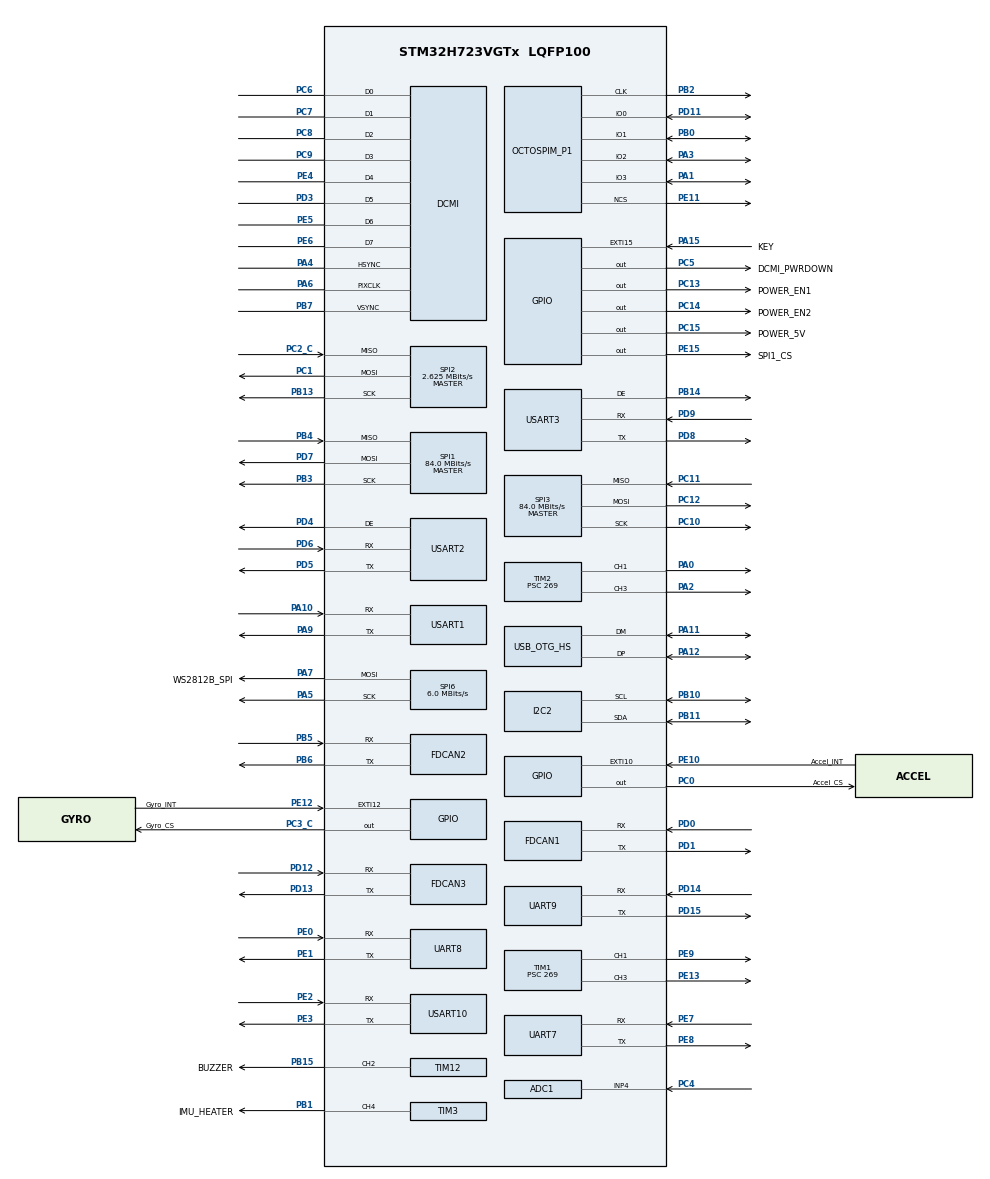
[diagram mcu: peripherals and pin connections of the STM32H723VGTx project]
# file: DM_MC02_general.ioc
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ADC1.Channel-1\#ChannelRegularConversion=ADC_CHANNEL_4
ADC1.ClockPrescaler=ADC_CLOCK_ASYNC_DIV1
ADC1.NbrOfConversionFlag=1
ADC1.OffsetNumber-1\#ChannelRegularConversion=ADC_OFFSET_NONE
ADC1.OffsetSignedSaturation-1\#ChannelRegularConversion=DISABLE
ADC1.Rank-1\#ChannelRegularConversion=1
ADC1.Resolution=ADC_RESOLUTION_16B
ADC1.SamplingTime-1\#ChannelRegularConversion=ADC_SAMPLETIME_64CYCLES_5
ADC1.master=1
ADC3.Channel-0\#ChannelRegularConversion=ADC_CHANNEL_TEMPSENSOR
ADC3.ClockPrescalerADC3=ADC_CLOCK_ASYNC_DIV4
ADC3.NbrOfConversionFlag=1
ADC3.OffsetNumber-0\#ChannelRegularConversion=ADC_OFFSET_NONE
ADC3.OffsetSign-0\#ChannelRegularConversion=ADC3_OFFSET_SIGN_NEGATIVE
ADC3.Rank-0\#ChannelRegularConversion=1
ADC3.ResolutionADC3=ADC_RESOLUTION_12B
ADC3.SamplingTime-0\#ChannelRegularConversion=ADC3_SAMPLETIME_640CYCLES_5
CORTEX_M7.AccessPermission-Cortex_Memory_Protection_Unit_Region0_Settings=MPU_REGION_FULL_ACCESS
CORTEX_M7.BaseAddress-Cortex_Memory_Protection_Unit_Region0_Settings=0x24000000
CORTEX_M7.CPU_DCache=Disabled
CORTEX_M7.CPU_ICache=Disabled
CORTEX_M7.Enable-Cortex_Memory_Protection_Unit_Region0_Settings=MPU_REGION_ENABLE
CORTEX_M7.IsBufferable-Cortex_Memory_Protection_Unit_Region0_Settings=MPU_ACCESS_BUFFERABLE
CORTEX_M7.IsCacheable-Cortex_Memory_Protection_Unit_Region0_Settings=MPU_ACCESS_CACHEABLE
CORTEX_M7.MPU_Control=__NULL
CORTEX_M7.Size-Cortex_Memory_Protection_Unit_Region0_Settings=MPU_REGION_SIZE_512KB
CORTEX_M7.TypeExtField-Cortex_Memory_Protection_Unit_Region0_Settings=MPU_TEX_LEVEL1
CORTEX_M7.default_mode_Activation=0
DCMI.JPEGMode=DCMI_JPEG_ENABLE
DCMI.PCKPolarity=DCMI_PCKPOLARITY_RISING
Dma.DCMI.10.Direction=DMA_PERIPH_TO_MEMORY
Dma.DCMI.10.EventEnable=DISABLE
Dma.DCMI.10.FIFOMode=DMA_FIFOMODE_DISABLE
Dma.DCMI.10.Instance=DMA2_Stream5
Dma.DCMI.10.MemDataAlignment=DMA_MDATAALIGN_WORD
Dma.DCMI.10.MemInc=DMA_MINC_ENABLE
Dma.DCMI.10.Mode=DMA_NORMAL
Dma.DCMI.10.PeriphDataAlignment=DMA_PDATAALIGN_WORD
Dma.DCMI.10.PeriphInc=DMA_PINC_DISABLE
Dma.DCMI.10.Polarity=HAL_DMAMUX_REQ_GEN_RISING
Dma.DCMI.10.Priority=DMA_PRIORITY_LOW
Dma.DCMI.10.RequestNumber=1
Dma.DCMI.10.SignalID=NONE
Dma.DCMI.10.SyncEnable=DISABLE
Dma.DCMI.10.SyncPolarity=HAL_DMAMUX_SYNC_NO_EVENT
Dma.DCMI.10.SyncRequestNumber=1
Dma.DCMI.10.SyncSignalID=NONE
Dma.Request0=USART1_RX
Dma.Request1=USART1_TX
Dma.Request10=DCMI
Dma.Request11=SPI1_TX
Dma.Request12=SPI1_RX
Dma.Request13=UART7_TX
Dma.Request14=USART10_RX
Dma.Request2=USART2_RX
Dma.Request3=USART2_TX
Dma.Request4=USART3_RX
Dma.Request5=UART8_RX
Dma.Request6=UART9_RX
Dma.Request7=UART7_RX
Dma.Request8=SPI2_RX
Dma.Request9=SPI2_TX
Dma.SPI1_RX.12.Direction=DMA_PERIPH_TO_MEMORY
Dma.SPI1_RX.12.EventEnable=DISABLE
Dma.SPI1_RX.12.FIFOMode=DMA_FIFOMODE_DISABLE
Dma.SPI1_RX.12.Instance=DMA2_Stream6
Dma.SPI1_RX.12.MemDataAlignment=DMA_MDATAALIGN_BYTE
Dma.SPI1_RX.12.MemInc=DMA_MINC_ENABLE
Dma.SPI1_RX.12.Mode=DMA_NORMAL
Dma.SPI1_RX.12.PeriphDataAlignment=DMA_PDATAALIGN_BYTE
Dma.SPI1_RX.12.PeriphInc=DMA_PINC_DISABLE
Dma.SPI1_RX.12.Polarity=HAL_DMAMUX_REQ_GEN_RISING
Dma.SPI1_RX.12.Priority=DMA_PRIORITY_MEDIUM
Dma.SPI1_RX.12.RequestNumber=1
Dma.SPI1_RX.12.SignalID=NONE
Dma.SPI1_RX.12.SyncEnable=DISABLE
Dma.SPI1_RX.12.SyncPolarity=HAL_DMAMUX_SYNC_NO_EVENT
Dma.SPI1_RX.12.SyncRequestNumber=1
Dma.SPI1_RX.12.SyncSignalID=NONE
Dma.SPI1_TX.11.Direction=DMA_MEMORY_TO_PERIPH
Dma.SPI1_TX.11.EventEnable=DISABLE
Dma.SPI1_TX.11.FIFOMode=DMA_FIFOMODE_DISABLE
Dma.SPI1_TX.11.Instance=DMA2_Stream7
Dma.SPI1_TX.11.MemDataAlignment=DMA_MDATAALIGN_BYTE
Dma.SPI1_TX.11.MemInc=DMA_MINC_ENABLE
Dma.SPI1_TX.11.Mode=DMA_NORMAL
Dma.SPI1_TX.11.PeriphDataAlignment=DMA_PDATAALIGN_BYTE
Dma.SPI1_TX.11.PeriphInc=DMA_PINC_DISABLE
Dma.SPI1_TX.11.Polarity=HAL_DMAMUX_REQ_GEN_RISING
Dma.SPI1_TX.11.Priority=DMA_PRIORITY_MEDIUM
Dma.SPI1_TX.11.RequestNumber=1
Dma.SPI1_TX.11.SignalID=NONE
Dma.SPI1_TX.11.SyncEnable=DISABLE
Dma.SPI1_TX.11.SyncPolarity=HAL_DMAMUX_SYNC_NO_EVENT
Dma.SPI1_TX.11.SyncRequestNumber=1
Dma.SPI1_TX.11.SyncSignalID=NONE
Dma.SPI2_RX.8.Direction=DMA_PERIPH_TO_MEMORY
Dma.SPI2_RX.8.EventEnable=DISABLE
Dma.SPI2_RX.8.FIFOMode=DMA_FIFOMODE_DISABLE
Dma.SPI2_RX.8.Instance=DMA2_Stream2
Dma.SPI2_RX.8.MemDataAlignment=DMA_MDATAALIGN_BYTE
Dma.SPI2_RX.8.MemInc=DMA_MINC_ENABLE
Dma.SPI2_RX.8.Mode=DMA_NORMAL
Dma.SPI2_RX.8.PeriphDataAlignment=DMA_PDATAALIGN_BYTE
Dma.SPI2_RX.8.PeriphInc=DMA_PINC_DISABLE
Dma.SPI2_RX.8.Polarity=HAL_DMAMUX_REQ_GEN_RISING
Dma.SPI2_RX.8.Priority=DMA_PRIORITY_VERY_HIGH
Dma.SPI2_RX.8.RequestNumber=1
Dma.SPI2_RX.8.SignalID=NONE
Dma.SPI2_RX.8.SyncEnable=DISABLE
Dma.SPI2_RX.8.SyncPolarity=HAL_DMAMUX_SYNC_NO_EVENT
Dma.SPI2_RX.8.SyncRequestNumber=1
Dma.SPI2_RX.8.SyncSignalID=NONE
Dma.SPI2_TX.9.Direction=DMA_MEMORY_TO_PERIPH
Dma.SPI2_TX.9.EventEnable=DISABLE
Dma.SPI2_TX.9.FIFOMode=DMA_FIFOMODE_DISABLE
Dma.SPI2_TX.9.Instance=DMA2_Stream3
Dma.SPI2_TX.9.MemDataAlignment=DMA_MDATAALIGN_BYTE
Dma.SPI2_TX.9.MemInc=DMA_MINC_ENABLE
Dma.SPI2_TX.9.Mode=DMA_NORMAL
Dma.SPI2_TX.9.PeriphDataAlignment=DMA_PDATAALIGN_BYTE
Dma.SPI2_TX.9.PeriphInc=DMA_PINC_DISABLE
Dma.SPI2_TX.9.Polarity=HAL_DMAMUX_REQ_GEN_RISING
Dma.SPI2_TX.9.Priority=DMA_PRIORITY_HIGH
Dma.SPI2_TX.9.RequestNumber=1
Dma.SPI2_TX.9.SignalID=NONE
Dma.SPI2_TX.9.SyncEnable=DISABLE
Dma.SPI2_TX.9.SyncPolarity=HAL_DMAMUX_SYNC_NO_EVENT
Dma.SPI2_TX.9.SyncRequestNumber=1
Dma.SPI2_TX.9.SyncSignalID=NONE
Dma.UART7_RX.7.Direction=DMA_PERIPH_TO_MEMORY
Dma.UART7_RX.7.EventEnable=DISABLE
Dma.UART7_RX.7.FIFOMode=DMA_FIFOMODE_DISABLE
Dma.UART7_RX.7.Instance=DMA2_Stream1
Dma.UART7_RX.7.MemDataAlignment=DMA_MDATAALIGN_BYTE
Dma.UART7_RX.7.MemInc=DMA_MINC_ENABLE
Dma.UART7_RX.7.Mode=DMA_NORMAL
Dma.UART7_RX.7.PeriphDataAlignment=DMA_PDATAALIGN_BYTE
Dma.UART7_RX.7.PeriphInc=DMA_PINC_DISABLE
Dma.UART7_RX.7.Polarity=HAL_DMAMUX_REQ_GEN_RISING
Dma.UART7_RX.7.Priority=DMA_PRIORITY_VERY_HIGH
Dma.UART7_RX.7.RequestNumber=1
Dma.UART7_RX.7.SignalID=NONE
Dma.UART7_RX.7.SyncEnable=DISABLE
Dma.UART7_RX.7.SyncPolarity=HAL_DMAMUX_SYNC_NO_EVENT
Dma.UART7_RX.7.SyncRequestNumber=1
Dma.UART7_RX.7.SyncSignalID=NONE
Dma.UART7_TX.13.Direction=DMA_MEMORY_TO_PERIPH
Dma.UART7_TX.13.EventEnable=DISABLE
Dma.UART7_TX.13.FIFOMode=DMA_FIFOMODE_DISABLE
Dma.UART7_TX.13.Instance=DMA2_Stream4
Dma.UART7_TX.13.MemDataAlignment=DMA_MDATAALIGN_BYTE
Dma.UART7_TX.13.MemInc=DMA_MINC_ENABLE
Dma.UART7_TX.13.Mode=DMA_NORMAL
Dma.UART7_TX.13.PeriphDataAlignment=DMA_PDATAALIGN_BYTE
Dma.UART7_TX.13.PeriphInc=DMA_PINC_DISABLE
Dma.UART7_TX.13.Polarity=HAL_DMAMUX_REQ_GEN_RISING
Dma.UART7_TX.13.Priority=DMA_PRIORITY_VERY_HIGH
Dma.UART7_TX.13.RequestNumber=1
Dma.UART7_TX.13.SignalID=NONE
Dma.UART7_TX.13.SyncEnable=DISABLE
Dma.UART7_TX.13.SyncPolarity=HAL_DMAMUX_SYNC_NO_EVENT
Dma.UART7_TX.13.SyncRequestNumber=1
Dma.UART7_TX.13.SyncSignalID=NONE
Dma.UART8_RX.5.Direction=DMA_PERIPH_TO_MEMORY
Dma.UART8_RX.5.EventEnable=DISABLE
Dma.UART8_RX.5.FIFOMode=DMA_FIFOMODE_DISABLE
Dma.UART8_RX.5.Instance=DMA1_Stream6
Dma.UART8_RX.5.MemDataAlignment=DMA_MDATAALIGN_BYTE
Dma.UART8_RX.5.MemInc=DMA_MINC_ENABLE
Dma.UART8_RX.5.Mode=DMA_NORMAL
Dma.UART8_RX.5.PeriphDataAlignment=DMA_PDATAALIGN_BYTE
Dma.UART8_RX.5.PeriphInc=DMA_PINC_DISABLE
Dma.UART8_RX.5.Polarity=HAL_DMAMUX_REQ_GEN_RISING
Dma.UART8_RX.5.Priority=DMA_PRIORITY_MEDIUM
Dma.UART8_RX.5.RequestNumber=1
Dma.UART8_RX.5.SignalID=NONE
Dma.UART8_RX.5.SyncEnable=DISABLE
Dma.UART8_RX.5.SyncPolarity=HAL_DMAMUX_SYNC_NO_EVENT
Dma.UART8_RX.5.SyncRequestNumber=1
Dma.UART8_RX.5.SyncSignalID=NONE
Dma.UART9_RX.6.Direction=DMA_PERIPH_TO_MEMORY
Dma.UART9_RX.6.EventEnable=DISABLE
Dma.UART9_RX.6.FIFOMode=DMA_FIFOMODE_DISABLE
Dma.UART9_RX.6.Instance=DMA1_Stream7
Dma.UART9_RX.6.MemDataAlignment=DMA_MDATAALIGN_BYTE
Dma.UART9_RX.6.MemInc=DMA_MINC_ENABLE
Dma.UART9_RX.6.Mode=DMA_NORMAL
Dma.UART9_RX.6.PeriphDataAlignment=DMA_PDATAALIGN_BYTE
Dma.UART9_RX.6.PeriphInc=DMA_PINC_DISABLE
Dma.UART9_RX.6.Polarity=HAL_DMAMUX_REQ_GEN_RISING
Dma.UART9_RX.6.Priority=DMA_PRIORITY_MEDIUM
Dma.UART9_RX.6.RequestNumber=1
Dma.UART9_RX.6.SignalID=NONE
Dma.UART9_RX.6.SyncEnable=DISABLE
Dma.UART9_RX.6.SyncPolarity=HAL_DMAMUX_SYNC_NO_EVENT
Dma.UART9_RX.6.SyncRequestNumber=1
Dma.UART9_RX.6.SyncSignalID=NONE
Dma.USART10_RX.14.Direction=DMA_PERIPH_TO_MEMORY
Dma.USART10_RX.14.EventEnable=DISABLE
Dma.USART10_RX.14.FIFOMode=DMA_FIFOMODE_DISABLE
Dma.USART10_RX.14.Instance=DMA1_Stream5
Dma.USART10_RX.14.MemDataAlignment=DMA_MDATAALIGN_BYTE
Dma.USART10_RX.14.MemInc=DMA_MINC_ENABLE
Dma.USART10_RX.14.Mode=DMA_NORMAL
Dma.USART10_RX.14.PeriphDataAlignment=DMA_PDATAALIGN_BYTE
Dma.USART10_RX.14.PeriphInc=DMA_PINC_DISABLE
Dma.USART10_RX.14.Polarity=HAL_DMAMUX_REQ_GEN_RISING
Dma.USART10_RX.14.Priority=DMA_PRIORITY_HIGH
Dma.USART10_RX.14.RequestNumber=1
Dma.USART10_RX.14.SignalID=NONE
Dma.USART10_RX.14.SyncEnable=DISABLE
Dma.USART10_RX.14.SyncPolarity=HAL_DMAMUX_SYNC_NO_EVENT
Dma.USART10_RX.14.SyncRequestNumber=1
Dma.USART10_RX.14.SyncSignalID=NONE
Dma.USART1_RX.0.Direction=DMA_PERIPH_TO_MEMORY
Dma.USART1_RX.0.EventEnable=DISABLE
Dma.USART1_RX.0.FIFOMode=DMA_FIFOMODE_DISABLE
Dma.USART1_RX.0.Instance=DMA1_Stream0
Dma.USART1_RX.0.MemDataAlignment=DMA_MDATAALIGN_BYTE
Dma.USART1_RX.0.MemInc=DMA_MINC_ENABLE
Dma.USART1_RX.0.Mode=DMA_NORMAL
Dma.USART1_RX.0.PeriphDataAlignment=DMA_PDATAALIGN_BYTE
Dma.USART1_RX.0.PeriphInc=DMA_PINC_DISABLE
Dma.USART1_RX.0.Polarity=HAL_DMAMUX_REQ_GEN_RISING
Dma.USART1_RX.0.Priority=DMA_PRIORITY_VERY_HIGH
Dma.USART1_RX.0.RequestNumber=1
Dma.USART1_RX.0.SignalID=NONE
Dma.USART1_RX.0.SyncEnable=DISABLE
Dma.USART1_RX.0.SyncPolarity=HAL_DMAMUX_SYNC_NO_EVENT
Dma.USART1_RX.0.SyncRequestNumber=1
Dma.USART1_RX.0.SyncSignalID=NONE
Dma.USART1_TX.1.Direction=DMA_MEMORY_TO_PERIPH
Dma.USART1_TX.1.EventEnable=DISABLE
Dma.USART1_TX.1.FIFOMode=DMA_FIFOMODE_DISABLE
Dma.USART1_TX.1.Instance=DMA1_Stream1
Dma.USART1_TX.1.MemDataAlignment=DMA_MDATAALIGN_BYTE
Dma.USART1_TX.1.MemInc=DMA_MINC_ENABLE
Dma.USART1_TX.1.Mode=DMA_NORMAL
Dma.USART1_TX.1.PeriphDataAlignment=DMA_PDATAALIGN_BYTE
Dma.USART1_TX.1.PeriphInc=DMA_PINC_DISABLE
Dma.USART1_TX.1.Polarity=HAL_DMAMUX_REQ_GEN_RISING
Dma.USART1_TX.1.Priority=DMA_PRIORITY_VERY_HIGH
Dma.USART1_TX.1.RequestNumber=1
Dma.USART1_TX.1.SignalID=NONE
Dma.USART1_TX.1.SyncEnable=DISABLE
Dma.USART1_TX.1.SyncPolarity=HAL_DMAMUX_SYNC_NO_EVENT
Dma.USART1_TX.1.SyncRequestNumber=1
Dma.USART1_TX.1.SyncSignalID=NONE
Dma.USART2_RX.2.Direction=DMA_PERIPH_TO_MEMORY
Dma.USART2_RX.2.EventEnable=DISABLE
Dma.USART2_RX.2.FIFOMode=DMA_FIFOMODE_DISABLE
Dma.USART2_RX.2.Instance=DMA1_Stream2
Dma.USART2_RX.2.MemDataAlignment=DMA_MDATAALIGN_BYTE
Dma.USART2_RX.2.MemInc=DMA_MINC_ENABLE
Dma.USART2_RX.2.Mode=DMA_NORMAL
Dma.USART2_RX.2.PeriphDataAlignment=DMA_PDATAALIGN_BYTE
Dma.USART2_RX.2.PeriphInc=DMA_PINC_DISABLE
Dma.USART2_RX.2.Polarity=HAL_DMAMUX_REQ_GEN_RISING
Dma.USART2_RX.2.Priority=DMA_PRIORITY_VERY_HIGH
Dma.USART2_RX.2.RequestNumber=1
Dma.USART2_RX.2.SignalID=NONE
Dma.USART2_RX.2.SyncEnable=DISABLE
Dma.USART2_RX.2.SyncPolarity=HAL_DMAMUX_SYNC_NO_EVENT
Dma.USART2_RX.2.SyncRequestNumber=1
Dma.USART2_RX.2.SyncSignalID=NONE
Dma.USART2_TX.3.Direction=DMA_MEMORY_TO_PERIPH
Dma.USART2_TX.3.EventEnable=DISABLE
Dma.USART2_TX.3.FIFOMode=DMA_FIFOMODE_DISABLE
Dma.USART2_TX.3.Instance=DMA1_Stream3
Dma.USART2_TX.3.MemDataAlignment=DMA_MDATAALIGN_BYTE
Dma.USART2_TX.3.MemInc=DMA_MINC_ENABLE
Dma.USART2_TX.3.Mode=DMA_NORMAL
Dma.USART2_TX.3.PeriphDataAlignment=DMA_PDATAALIGN_BYTE
Dma.USART2_TX.3.PeriphInc=DMA_PINC_DISABLE
Dma.USART2_TX.3.Polarity=HAL_DMAMUX_REQ_GEN_RISING
Dma.USART2_TX.3.Priority=DMA_PRIORITY_VERY_HIGH
Dma.USART2_TX.3.RequestNumber=1
Dma.USART2_TX.3.SignalID=NONE
Dma.USART2_TX.3.SyncEnable=DISABLE
Dma.USART2_TX.3.SyncPolarity=HAL_DMAMUX_SYNC_NO_EVENT
Dma.USART2_TX.3.SyncRequestNumber=1
Dma.USART2_TX.3.SyncSignalID=NONE
Dma.USART3_RX.4.Direction=DMA_PERIPH_TO_MEMORY
Dma.USART3_RX.4.EventEnable=DISABLE
Dma.USART3_RX.4.FIFOMode=DMA_FIFOMODE_DISABLE
Dma.USART3_RX.4.Instance=DMA1_Stream4
Dma.USART3_RX.4.MemDataAlignment=DMA_MDATAALIGN_BYTE
Dma.USART3_RX.4.MemInc=DMA_MINC_ENABLE
Dma.USART3_RX.4.Mode=DMA_NORMAL
Dma.USART3_RX.4.PeriphDataAlignment=DMA_PDATAALIGN_BYTE
Dma.USART3_RX.4.PeriphInc=DMA_PINC_DISABLE
Dma.USART3_RX.4.Polarity=HAL_DMAMUX_REQ_GEN_RISING
Dma.USART3_RX.4.Priority=DMA_PRIORITY_MEDIUM
Dma.USART3_RX.4.RequestNumber=1
Dma.USART3_RX.4.SignalID=NONE
Dma.USART3_RX.4.SyncEnable=DISABLE
Dma.USART3_RX.4.SyncPolarity=HAL_DMAMUX_SYNC_NO_EVENT
Dma.USART3_RX.4.SyncRequestNumber=1
Dma.USART3_RX.4.SyncSignalID=NONE
FDCAN1.AutoRetransmission=ENABLE
FDCAN1.CalculateBaudRateNominal=1000000
FDCAN1.CalculateTimeBitNominal=1000
FDCAN1.CalculateTimeQuantumNominal=166.66666666666666
FDCAN1.NominalPrescaler=4
FDCAN1.NominalTimeSeg1=3
FDCAN1.RxFifo0ElmtsNbr=32
FDCAN1.StdFiltersNbr=1
FDCAN1.TxFifoQueueElmtsNbr=32
FDCAN2.AutoRetransmission=ENABLE
FDCAN2.CalculateBaudRateNominal=1000000
FDCAN2.CalculateTimeBitNominal=1000
FDCAN2.CalculateTimeQuantumNominal=166.66666666666666
FDCAN2.ClockCalibrationCCU=DISABLE
FDCAN2.MessageRAMOffset=0x406
FDCAN2.NominalPrescaler=4
FDCAN2.NominalTimeSeg1=3
FDCAN2.RxFifo0ElmtsNbr=32
FDCAN2.StdFiltersNbr=1
FDCAN2.TxFifoQueueElmtsNbr=32
FDCAN3.AutoRetransmission=ENABLE
FDCAN3.CalculateBaudRateNominal=1000000
FDCAN3.CalculateTimeBitNominal=1000
FDCAN3.CalculateTimeQuantumNominal=166.66666666666666
FDCAN3.MessageRAMOffset=0x812
FDCAN3.NominalPrescaler=4
FDCAN3.NominalTimeSeg1=3
FDCAN3.RxFifo0ElmtsNbr=32
FDCAN3.StdFiltersNbr=1
FDCAN3.TxFifoQueueElmtsNbr=32
FREERTOS.INCLUDE_xTaskAbortDelay=0
FREERTOS.INCLUDE_xTaskGetHandle=0
FREERTOS.Tasks01=defaultTask,24,1024,StartDefaultTask,Default,NULL,Dynamic,NULL,NULL
FREERTOS.configCHECK_FOR_STACK_OVERFLOW=2
FREERTOS.configENABLE_FPU=1
FREERTOS.configGENERATE_RUN_TIME_STATS=1
FREERTOS.configTOTAL_HEAP_SIZE=262144
FREERTOS.configUSE_NEWLIB_REENTRANT=1
I2C2.Timing=0x20303E5D
Mcu.Family=STM32H7
Mcu.Name=STM32H723VGTx
Mcu.Package=LQFP100
NVIC.DMA1_Stream0_IRQn=true\:5\:0\:false\:false\:true\:true\:false\:true\:true
NVIC.DMA1_Stream1_IRQn=true\:5\:0\:false\:false\:true\:true\:false\:true\:true
NVIC.DMA1_Stream2_IRQn=true\:5\:0\:false\:false\:true\:true\:false\:true\:true
NVIC.DMA1_Stream3_IRQn=true\:5\:0\:false\:false\:true\:true\:false\:true\:true
NVIC.DMA1_Stream4_IRQn=true\:5\:0\:false\:false\:true\:true\:false\:true\:true
NVIC.DMA1_Stream5_IRQn=true\:5\:0\:false\:false\:true\:true\:false\:true\:true
NVIC.DMA1_Stream6_IRQn=true\:5\:0\:false\:false\:true\:true\:false\:true\:true
NVIC.DMA1_Stream7_IRQn=true\:5\:0\:false\:false\:true\:true\:false\:true\:true
NVIC.DMA2_Stream1_IRQn=true\:5\:0\:false\:false\:true\:true\:false\:true\:true
NVIC.DMA2_Stream2_IRQn=true\:5\:0\:false\:false\:true\:true\:false\:true\:true
NVIC.DMA2_Stream3_IRQn=true\:5\:0\:false\:false\:true\:true\:false\:true\:true
NVIC.DMA2_Stream4_IRQn=true\:5\:0\:true\:false\:true\:false\:false\:true\:true
NVIC.DMA2_Stream5_IRQn=true\:5\:0\:true\:false\:true\:false\:false\:true\:true
NVIC.DMA2_Stream6_IRQn=true\:5\:0\:false\:false\:true\:true\:false\:true\:true
NVIC.DMA2_Stream7_IRQn=true\:5\:0\:true\:false\:true\:false\:false\:true\:true
NVIC.EXTI15_10_IRQn=true\:5\:0\:false\:false\:true\:true\:true\:true\:true
NVIC.FDCAN1_IT0_IRQn=true\:5\:0\:false\:false\:true\:true\:true\:true\:true
NVIC.FDCAN1_IT1_IRQn=true\:5\:0\:false\:false\:true\:true\:true\:true\:true
NVIC.FDCAN2_IT0_IRQn=true\:5\:0\:false\:false\:true\:true\:true\:true\:true
NVIC.FDCAN2_IT1_IRQn=true\:5\:0\:false\:false\:true\:true\:true\:true\:true
NVIC.FDCAN3_IT0_IRQn=true\:5\:0\:false\:false\:true\:true\:true\:true\:true
NVIC.FDCAN3_IT1_IRQn=true\:5\:0\:false\:false\:true\:true\:true\:true\:true
NVIC.I2C2_ER_IRQn=true\:5\:0\:false\:false\:true\:true\:true\:true\:true
NVIC.I2C2_EV_IRQn=true\:5\:0\:false\:false\:true\:true\:true\:true\:true
NVIC.OTG_HS_EP1_IN_IRQn=true\:5\:0\:false\:false\:true\:true\:false\:true\:true
NVIC.OTG_HS_EP1_OUT_IRQn=true\:5\:0\:false\:false\:true\:true\:false\:true\:true
NVIC.OTG_HS_IRQn=true\:5\:0\:false\:false\:true\:true\:false\:true\:true
NVIC.PriorityGroup=NVIC_PRIORITYGROUP_4
NVIC.SPI1_IRQn=true\:5\:0\:false\:false\:true\:true\:false\:true\:true
NVIC.SPI2_IRQn=true\:5\:0\:false\:false\:true\:true\:false\:true\:true
NVIC.SPI3_IRQn=true\:5\:0\:false\:false\:true\:true\:true\:true\:true
NVIC.SPI6_IRQn=true\:5\:0\:false\:false\:true\:true\:true\:true\:true
NVIC.TIM17_IRQn=true\:0\:0\:true\:false\:true\:false\:false\:true\:true
NVIC.TimeBase=TIM17_IRQn
NVIC.TimeBaseIP=TIM17
NVIC.UART7_IRQn=true\:5\:0\:false\:false\:true\:true\:true\:true\:true
NVIC.UART8_IRQn=true\:5\:0\:false\:false\:true\:true\:true\:true\:true
NVIC.UART9_IRQn=true\:5\:0\:false\:false\:true\:true\:true\:true\:true
NVIC.USART10_IRQn=true\:5\:0\:false\:false\:true\:true\:true\:true\:true
NVIC.USART1_IRQn=true\:5\:0\:false\:false\:true\:true\:true\:true\:true
NVIC.USART2_IRQn=true\:5\:0\:false\:false\:true\:true\:true\:true\:true
NVIC.USART3_IRQn=true\:5\:0\:false\:false\:true\:true\:true\:true\:true
OCTOSPI2.ClockMode=HAL_OSPI_CLOCK_MODE_3
OCTOSPI2.ClockPrescaler=3
OCTOSPI2.DeviceSize=23
OCTOSPI2.DeviceType=SPI_DEVICE_FLASH
OCTOSPI2.SampleShifting=HAL_OSPI_SAMPLE_SHIFTING_HALFCYCLE
PA0.GPIO_Speed=GPIO_SPEED_FREQ_VERY_HIGH
PA0.Signal=S_TIM2_CH1_ETR
PA1.Mode=OCTOSPI2_IOL_Port1L
PA1.Signal=OCTOSPIM_P1_IO3
PA10.GPIO_Speed=GPIO_SPEED_FREQ_VERY_HIGH
PA10.Mode=Asynchronous
PA10.Signal=USART1_RX
PA11.Mode=Device_Only_FS
PA11.Signal=USB_OTG_HS_DM
PA12.Mode=Device_Only_FS
PA12.Signal=USB_OTG_HS_DP
PA13(JTMS/SWDIO).Mode=Serial_Wire
PA13(JTMS/SWDIO).Signal=DEBUG_JTMS-SWDIO
PA14(JTCK/SWCLK).Mode=Serial_Wire
PA14(JTCK/SWCLK).Signal=DEBUG_JTCK-SWCLK
PA15(JTDI).GPIO_Label=KEY
PA15(JTDI).Signal=GPXTI15
PA2.GPIO_Speed=GPIO_SPEED_FREQ_VERY_HIGH
PA2.Signal=S_TIM2_CH3
PA3.Mode=OCTOSPI2_IOL_Port1L
PA3.Signal=OCTOSPIM_P1_IO2
PA4.Mode=Slave_8_bits_External_Synchro
PA4.Signal=DCMI_HSYNC
PA5.Mode=TX_Only_Simplex_Unidirect_Master
PA5.Signal=SPI6_SCK
PA6.Mode=Slave_8_bits_External_Synchro
PA6.Signal=DCMI_PIXCLK
PA7.GPIO_Label=WS2812B_SPI
PA7.GPIO_Speed=GPIO_SPEED_FREQ_VERY_HIGH
PA7.Mode=TX_Only_Simplex_Unidirect_Master
PA7.Signal=SPI6_MOSI
PA8.Signal=RCC_MCO_1
PA9.GPIO_Speed=GPIO_SPEED_FREQ_VERY_HIGH
PA9.Mode=Asynchronous
PA9.Signal=USART1_TX
PB0.Mode=OCTOSPI2_IOL_Port1L
PB0.Signal=OCTOSPIM_P1_IO1
PB1.GPIO_Label=IMU_HEATER
PB1.GPIO_Speed=GPIO_SPEED_FREQ_VERY_HIGH
PB1.Signal=S_TIM3_CH4
PB10.GPIO_Pu=GPIO_PULLUP
PB10.GPIO_Speed=GPIO_SPEED_FREQ_VERY_HIGH
PB10.Mode=I2C
PB10.Signal=I2C2_SCL
PB11.GPIO_Pu=GPIO_PULLUP
PB11.GPIO_Speed=GPIO_SPEED_FREQ_VERY_HIGH
PB11.Mode=I2C
PB11.Signal=I2C2_SDA
PB13.GPIO_Speed=GPIO_SPEED_FREQ_VERY_HIGH
PB13.Mode=Full_Duplex_Master
PB13.Signal=SPI2_SCK
PB14.GPIO_Speed=GPIO_SPEED_FREQ_VERY_HIGH
PB14.Mode=Hardware Flow Control (RS485)
PB14.Signal=USART3_DE
PB15.GPIO_Label=BUZZER
PB15.GPIO_Speed=GPIO_SPEED_FREQ_VERY_HIGH
PB15.Signal=S_TIM12_CH2
PB2.Mode=O2_P1_CLK
PB2.Signal=OCTOSPIM_P1_CLK
PB3(JTDO/TRACESWO).GPIO_Speed=GPIO_SPEED_FREQ_VERY_HIGH
PB3(JTDO/TRACESWO).Mode=Full_Duplex_Master
PB3(JTDO/TRACESWO).Signal=SPI1_SCK
PB4(NJTRST).GPIO_Speed=GPIO_SPEED_FREQ_VERY_HIGH
PB4(NJTRST).Mode=Full_Duplex_Master
PB4(NJTRST).Signal=SPI1_MISO
PB5.GPIO_Speed=GPIO_SPEED_FREQ_MEDIUM
PB5.Mode=FDCAN_Activate
PB5.Signal=FDCAN2_RX
PB6.GPIO_Speed=GPIO_SPEED_FREQ_MEDIUM
PB6.Mode=FDCAN_Activate
PB6.Signal=FDCAN2_TX
PB7.Mode=Slave_8_bits_External_Synchro
PB7.Signal=DCMI_VSYNC
PC0.GPIO_Label=Accel_CS
PC0.GPIO_Speed=GPIO_SPEED_FREQ_VERY_HIGH
PC0.PinState=GPIO_PIN_SET
PC0.Signal=GPIO_Output
PC1.GPIO_Speed=GPIO_SPEED_FREQ_VERY_HIGH
PC1.Mode=Full_Duplex_Master
PC1.Signal=SPI2_MOSI
PC10.Mode=Full_Duplex_Master
PC10.Signal=SPI3_SCK
PC11.Mode=Full_Duplex_Master
PC11.Signal=SPI3_MISO
PC12.Mode=Full_Duplex_Master
PC12.Signal=SPI3_MOSI
PC13.GPIO_Label=POWER_EN1
PC13.Signal=GPIO_Output
PC14-OSC32_IN.GPIO_Label=POWER_EN2
PC14-OSC32_IN.Signal=GPIO_Output
PC15-OSC32_OUT.GPIO_Label=POWER_5V
PC15-OSC32_OUT.Signal=GPIO_Output
PC2_C.GPIO_Speed=GPIO_SPEED_FREQ_VERY_HIGH
PC2_C.Mode=Full_Duplex_Master
PC2_C.Signal=SPI2_MISO
PC3_C.GPIO_Label=Gyro_CS
PC3_C.GPIO_Speed=GPIO_SPEED_FREQ_VERY_HIGH
PC3_C.PinState=GPIO_PIN_SET
PC3_C.Signal=GPIO_Output
PC4.Signal=ADCx_INP4
PC5.GPIO_Label=DCMI_PWRDOWN
PC5.Signal=GPIO_Output
PC6.Mode=Slave_8_bits_External_Synchro
PC6.Signal=DCMI_D0
PC7.Mode=Slave_8_bits_External_Synchro
PC7.Signal=DCMI_D1
PC8.Mode=Slave_8_bits_External_Synchro
PC8.Signal=DCMI_D2
PC9.Mode=Slave_8_bits_External_Synchro
PC9.Signal=DCMI_D3
PD0.GPIO_Speed=GPIO_SPEED_FREQ_MEDIUM
PD0.Mode=FDCAN_Activate
PD0.Signal=FDCAN1_RX
PD1.GPIO_Speed=GPIO_SPEED_FREQ_MEDIUM
PD1.Mode=FDCAN_Activate
PD1.Signal=FDCAN1_TX
PD11.Mode=OCTOSPI2_IOL_Port1L
PD11.Signal=OCTOSPIM_P1_IO0
PD12.GPIO_Speed=GPIO_SPEED_FREQ_MEDIUM
PD12.Mode=FDCAN_Activate
PD12.Signal=FDCAN3_RX
PD13.GPIO_Speed=GPIO_SPEED_FREQ_MEDIUM
PD13.Mode=FDCAN_Activate
PD13.Signal=FDCAN3_TX
PD14.GPIO_Speed=GPIO_SPEED_FREQ_VERY_HIGH
PD14.Mode=Asynchronous
PD14.Signal=UART9_RX
PD15.GPIO_Speed=GPIO_SPEED_FREQ_VERY_HIGH
PD15.Mode=Asynchronous
PD15.Signal=UART9_TX
PD2.GPIO_Label=DBUS
PD2.GPIO_Speed=GPIO_SPEED_FREQ_VERY_HIGH
PD2.Signal=UART5_RX
PD3.Mode=Slave_8_bits_External_Synchro
PD3.Signal=DCMI_D5
PD4.GPIO_Speed=GPIO_SPEED_FREQ_VERY_HIGH
PD4.Mode=Hardware Flow Control (RS485)
PD4.Signal=USART2_DE
PD5.GPIO_Speed=GPIO_SPEED_FREQ_VERY_HIGH
PD5.Mode=Asynchronous
PD5.Signal=USART2_TX
PD6.GPIO_Speed=GPIO_SPEED_FREQ_VERY_HIGH
PD6.Mode=Asynchronous
PD6.Signal=USART2_RX
PD7.GPIO_Speed=GPIO_SPEED_FREQ_VERY_HIGH
PD7.Mode=Full_Duplex_Master
PD7.Signal=SPI1_MOSI
PD8.GPIO_Speed=GPIO_SPEED_FREQ_VERY_HIGH
PD8.Mode=Asynchronous
PD8.Signal=USART3_TX
PD9.GPIO_Speed=GPIO_SPEED_FREQ_VERY_HIGH
PD9.Mode=Asynchronous
PD9.Signal=USART3_RX
PE0.GPIO_Speed=GPIO_SPEED_FREQ_VERY_HIGH
PE0.Mode=Asynchronous
PE0.Signal=UART8_RX
PE1.GPIO_Speed=GPIO_SPEED_FREQ_VERY_HIGH
PE1.Mode=Asynchronous
PE1.Signal=UART8_TX
PE10.GPIO_Label=Accel_INT
PE10.Signal=GPXTI10
PE11.Mode=OCTOSPI2_Port1_NCS
PE11.Signal=OCTOSPIM_P1_NCS
PE12.GPIO_Label=Gyro_INT
PE12.Signal=GPXTI12
PE13.GPIO_Speed=GPIO_SPEED_FREQ_VERY_HIGH
PE13.Signal=S_TIM1_CH3
PE15.GPIO_Label=SPI1_CS
PE15.GPIO_Speed=GPIO_SPEED_FREQ_VERY_HIGH
PE15.Signal=GPIO_Output
PE2.GPIO_Speed=GPIO_SPEED_FREQ_VERY_HIGH
PE2.Mode=Asynchronous
PE2.Signal=USART10_RX
PE3.GPIO_Speed=GPIO_SPEED_FREQ_VERY_HIGH
PE3.Mode=Asynchronous
PE3.Signal=USART10_TX
PE4.Mode=Slave_8_bits_External_Synchro
PE4.Signal=DCMI_D4
PE5.Mode=Slave_8_bits_External_Synchro
PE5.Signal=DCMI_D6
PE6.Mode=Slave_8_bits_External_Synchro
PE6.Signal=DCMI_D7
PE7.GPIO_Speed=GPIO_SPEED_FREQ_VERY_HIGH
PE7.Mode=Asynchronous
PE7.Signal=UART7_RX
PE8.GPIO_Speed=GPIO_SPEED_FREQ_VERY_HIGH
PE8.Mode=Asynchronous
PE8.Signal=UART7_TX
PE9.GPIO_Speed=GPIO_SPEED_FREQ_VERY_HIGH
PE9.Signal=S_TIM1_CH1
PH0-OSC_IN.Mode=HSE-External-Oscillator
PH0-OSC_IN.Signal=RCC_OSC_IN
PH1-OSC_OUT.Mode=HSE-External-Oscillator
PH1-OSC_OUT.Signal=RCC_OSC_OUT
ProjectManager.HeapSize=0x1000
ProjectManager.StackSize=0x2000
ProjectManager.TargetToolchain=Makefile
RCC.ADCCLockSelection=RCC_ADCCLKSOURCE_PLL3
RCC.ADCFreq_Value=48000000
RCC.APB1Freq_Value=135000000
RCC.APB2Freq_Value=135000000
RCC.APB3Freq_Value=135000000
RCC.APB4Freq_Value=135000000
RCC.CortexFreq_Value=540000000
RCC.D1PPRE=RCC_APB3_DIV2
RCC.D2PPRE1=RCC_APB1_DIV2
RCC.D2PPRE2=RCC_APB2_DIV2
RCC.D3PPRE=RCC_APB4_DIV2
RCC.DIVM1=2
RCC.DIVM2=24
RCC.DIVM3=24
RCC.DIVN1=45
RCC.DIVN2=168
RCC.DIVN3=192
RCC.DIVP1=1
RCC.DIVP2=1
RCC.DIVP3=4
RCC.DIVQ3=4
RCC.DIVR3=4
RCC.FDCANCLockSelection=RCC_FDCANCLKSOURCE_HSE
RCC.FLatency-AdvancedSettings=FLASH_LATENCY_3
RCC.HCLKFreq_Value=270000000
RCC.HPRE=RCC_HCLK_DIV2
RCC.HSE_VALUE=24000000
RCC.I2C123CLockSelection=RCC_I2C1235CLKSOURCE_PLL3
RCC.PLL1_VCI_Range-AdvancedSettings=RCC_PLL1VCIRANGE_0
RCC.PLL1_VCO_SEL-AdvancedSettings=RCC_PLL1VCOMEDIUM
RCC.PLL2FRACN=0
RCC.PLL2_VCI_Range-AdvancedSettings=RCC_PLL2VCIRANGE_0
RCC.PLL3FRACN=0
RCC.PLLFRACN=0
RCC.PLLSourceVirtual=RCC_PLLSOURCE_HSE
RCC.SPI123CLockSelection=RCC_SPI123CLKSOURCE_PLL2
RCC.SPI6CLockSelection=RCC_SPI6CLKSOURCE_HSE
RCC.SYSCLKFreq_VALUE=540000000
RCC.SYSCLKSource=RCC_SYSCLKSOURCE_PLLCLK
RCC.USART16CLockSelection=RCC_USART16910CLKSOURCE_PLL2
RCC.USBCLockSelection=RCC_USBCLKSOURCE_PLL3
RCC.USBFreq_Value=48000000
SH.ADCx_INP4.0=ADC1_INP4,IN4-Single-Ended
SH.S_TIM12_CH2.0=TIM12_CH2,PWM Generation2 CH2
SH.S_TIM1_CH1.0=TIM1_CH1,PWM Generation1 CH1
SH.S_TIM1_CH3.0=TIM1_CH3,PWM Generation3 CH3
SH.S_TIM2_CH1_ETR.0=TIM2_CH1,PWM Generation1 CH1
SH.S_TIM2_CH3.0=TIM2_CH3,PWM Generation3 CH3
SH.S_TIM3_CH4.0=TIM3_CH4,PWM Generation4 CH4
SPI1.CalculateBaudRate=84.0 MBits/s
SPI1.Direction=SPI_DIRECTION_2LINES
SPI1.Mode=SPI_MODE_MASTER
SPI1.VirtualType=VM_MASTER
SPI2.BaudRatePrescaler=SPI_BAUDRATEPRESCALER_64
SPI2.CLKPhase=SPI_PHASE_2EDGE
SPI2.CLKPolarity=SPI_POLARITY_HIGH
SPI2.CalculateBaudRate=2.625 MBits/s
SPI2.DataSize=SPI_DATASIZE_8BIT
SPI2.Direction=SPI_DIRECTION_2LINES
SPI2.Mode=SPI_MODE_MASTER
SPI2.VirtualType=VM_MASTER
SPI3.CalculateBaudRate=84.0 MBits/s
SPI3.Direction=SPI_DIRECTION_2LINES
SPI3.Mode=SPI_MODE_MASTER
SPI3.VirtualType=VM_MASTER
SPI6.BaudRatePrescaler=SPI_BAUDRATEPRESCALER_4
SPI6.CLKPhase=SPI_PHASE_2EDGE
SPI6.CalculateBaudRate=6.0 MBits/s
SPI6.DataSize=SPI_DATASIZE_8BIT
SPI6.Direction=SPI_DIRECTION_2LINES_TXONLY
SPI6.Mode=SPI_MODE_MASTER
SPI6.VirtualType=VM_MASTER
TIM1.Channel-PWM\ Generation1\ CH1=TIM_CHANNEL_1
TIM1.Channel-PWM\ Generation3\ CH3=TIM_CHANNEL_3
TIM1.Period=19999
TIM1.Prescaler=269
TIM1.Pulse-PWM\ Generation1\ CH1=2000
TIM1.Pulse-PWM\ Generation3\ CH3=2000
TIM12.Channel-PWM\ Generation2\ CH2=TIM_CHANNEL_2
TIM12.Prescaler=269
TIM2.Channel-PWM\ Generation1\ CH1=TIM_CHANNEL_1
TIM2.Channel-PWM\ Generation3\ CH3=TIM_CHANNEL_3
TIM2.Period=19999
TIM2.Prescaler=269
TIM2.Pulse-PWM\ Generation1\ CH1=2000
TIM2.Pulse-PWM\ Generation3\ CH3=2000
TIM24.Prescaler=269
TIM3.Channel-PWM\ Generation4\ CH4=TIM_CHANNEL_4
TIM3.Period=19999
TIM3.Prescaler=269
USART1.OverrunDisableParam=ADVFEATURE_OVERRUN_ENABLE
USART1.VirtualMode-Asynchronous=VM_ASYNC
USART10.VirtualMode=VM_ASYNC
USART2.VirtualMode-Asynchronous=VM_ASYNC
USART2.VirtualMode-Hardware\ Flow\ Control\ (RS485)=VM_ASYNC
USART3.VirtualMode-Asynchronous=VM_ASYNC
USART3.VirtualMode-Hardware\ Flow\ Control\ (RS485)=VM_ASYNC
USB_DEVICE.CLASS_NAME_HS=CDC
USB_DEVICE.VirtualMode=Cdc
USB_DEVICE.VirtualModeHS=Cdc_HS
USB_OTG_HS.VirtualMode-Device_Only_FS=Device_Only_FS
USB_OTG_HS.dma_enable-Device_Only_FS=DISABLE
USB_OTG_HS.low_power_enable-Device_Only_FS=DISABLE
USB_OTG_HS.lpm_enable-Device_Only_FS=DISABLE
USB_OTG_HS.use_dedicated_ep1-Device_Only_FS=DISABLE
VP_ADC3_TempSens_Input.Mode=IN-TempSens
VP_FREERTOS_VS_CMSIS_V2.Mode=CMSIS_V2
VP_OCTOSPI2_VS_quad.Mode=quad_mode
VP_SYS_VS_tim17.Mode=TIM17
VP_TIM23_VS_ClockSourceINT.Mode=Internal
VP_TIM24_VS_ClockSourceINT.Mode=Internal
VP_USB_DEVICE_VS_USB_DEVICE_CDC_HS.Mode=CDC_HS
board=custom

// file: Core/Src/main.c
/* USER CODE BEGIN Header */
/**
  ******************************************************************************
  * @file           : main.c
  * @brief          : Main program body
  ******************************************************************************
  * @attention
  *
  * Copyright (c) 2024 STMicroelectronics.
  * All rights reserved.
  *
  * This software is licensed under terms that can be found in the LICENSE file
  * in the root directory of this software component.
  * If no LICENSE file comes with this software, it is provided AS-IS.
  *
  ******************************************************************************
  */
/* USER CODE END Header */
#include "main.h"
#include "cmsis_os.h"
#include "adc.h"
#include "dcmi.h"
#include "dma.h"
#include "fdcan.h"
#include "i2c.h"
#include "octospi.h"
#include "spi.h"
#include "tim.h"
#include "usart.h"
#include "usb_device.h"
#include "gpio.h"

void SystemClock_Config(void);
void PeriphCommonClock_Config(void);
void MX_FREERTOS_Init(void);

int main(void)
{

  /* MCU Configuration--------------------------------------------------------*/

  /* Reset of all peripherals, Initializes the Flash interface and the Systick. */
  HAL_Init();

  /* Configure the system clock */
  SystemClock_Config();

/* Configure the peripherals common clocks */
  PeriphCommonClock_Config();

  /* Initialize all configured peripherals */
  MX_GPIO_Init();
  MX_DMA_Init();
  MX_FDCAN3_Init();
  MX_I2C2_Init();
  MX_SPI1_Init();
  MX_SPI2_Init();
  MX_TIM1_Init();
  MX_TIM2_Init();
  MX_TIM3_Init();
  MX_UART7_Init();
  MX_UART8_Init();
  MX_UART9_Init();
  MX_USART1_UART_Init();
  MX_USART2_UART_Init();
  MX_USART3_UART_Init();
  MX_USART10_UART_Init();
  MX_DCMI_Init();
  MX_OCTOSPI2_Init();
  MX_TIM12_Init();
  MX_ADC1_Init();
  MX_ADC3_Init();
  MX_FDCAN1_Init();
  MX_FDCAN2_Init();
  MX_TIM23_Init();
  MX_TIM24_Init();
  MX_SPI3_Init();
  MX_SPI6_Init();
  /* USER CODE BEGIN 2 */
  if (HAL_ADCEx_Calibration_Start(&hadc1, ADC_CALIB_OFFSET, ADC_SINGLE_ENDED) != HAL_OK ||
      HAL_ADCEx_Calibration_Start(&hadc3, ADC_CALIB_OFFSET, ADC_SINGLE_ENDED) != HAL_OK) {
    Error_Handler();
  }
  RM_DMA_UART5_INIT();
  RM_UART5_Init();
  /* USER CODE END 2 */

  /* Init scheduler */
  osKernelInitialize();

  /* Call init function for freertos objects (in freertos.c) */
  MX_FREERTOS_Init();

  /* Start scheduler */
  osKernelStart();

  /* We should never get here as control is now taken by the scheduler */
  /* Infinite loop */
  while (1)
  {

  }
}

void SystemClock_Config(void)
{
  RCC_OscInitTypeDef RCC_OscInitStruct = {0};
  RCC_ClkInitTypeDef RCC_ClkInitStruct = {0};

  /** Supply configuration update enable
  */
  HAL_PWREx_ConfigSupply(PWR_LDO_SUPPLY);

  /** Configure the main internal regulator output voltage
  */
  __HAL_PWR_VOLTAGESCALING_CONFIG(PWR_REGULATOR_VOLTAGE_SCALE0);

  while(!__HAL_PWR_GET_FLAG(PWR_FLAG_VOSRDY)) {}

  /** Initializes the RCC Oscillators according to the specified parameters
  * in the RCC_OscInitTypeDef structure.
  */
  RCC_OscInitStruct.OscillatorType = RCC_OSCILLATORTYPE_HSE;
  RCC_OscInitStruct.HSEState = RCC_HSE_ON;
  RCC_OscInitStruct.PLL.PLLState = RCC_PLL_ON;
  RCC_OscInitStruct.PLL.PLLSource = RCC_PLLSOURCE_HSE;
  RCC_OscInitStruct.PLL.PLLM = 2;
  RCC_OscInitStruct.PLL.PLLN = 45;
  RCC_OscInitStruct.PLL.PLLP = 1;
  RCC_OscInitStruct.PLL.PLLQ = 2;
  RCC_OscInitStruct.PLL.PLLR = 2;
  RCC_OscInitStruct.PLL.PLLRGE = RCC_PLL1VCIRANGE_3;
  RCC_OscInitStruct.PLL.PLLVCOSEL = RCC_PLL1VCOWIDE;
  RCC_OscInitStruct.PLL.PLLFRACN = 0;
  if (HAL_RCC_OscConfig(&RCC_OscInitStruct) != HAL_OK)
  {
    Error_Handler();
  }

  /** Initializes the CPU, AHB and APB buses clocks
  */
  RCC_ClkInitStruct.ClockType = RCC_CLOCKTYPE_HCLK|RCC_CLOCKTYPE_SYSCLK
                              |RCC_CLOCKTYPE_PCLK1|RCC_CLOCKTYPE_PCLK2
                              |RCC_CLOCKTYPE_D3PCLK1|RCC_CLOCKTYPE_D1PCLK1;
  RCC_ClkInitStruct.SYSCLKSource = RCC_SYSCLKSOURCE_PLLCLK;
  RCC_ClkInitStruct.SYSCLKDivider = RCC_SYSCLK_DIV1;
  RCC_ClkInitStruct.AHBCLKDivider = RCC_HCLK_DIV2;
  RCC_ClkInitStruct.APB3CLKDivider = RCC_APB3_DIV2;
  RCC_ClkInitStruct.APB1CLKDivider = RCC_APB1_DIV2;
  RCC_ClkInitStruct.APB2CLKDivider = RCC_APB2_DIV2;
  RCC_ClkInitStruct.APB4CLKDivider = RCC_APB4_DIV2;

  if (HAL_RCC_ClockConfig(&RCC_ClkInitStruct, FLASH_LATENCY_3) != HAL_OK)
  {
    Error_Handler();
  }
}

void PeriphCommonClock_Config(void)
{
  RCC_PeriphCLKInitTypeDef PeriphClkInitStruct = {0};

  /** Initializes the peripherals clock
  */
  PeriphClkInitStruct.PeriphClockSelection = RCC_PERIPHCLK_USB|RCC_PERIPHCLK_ADC
                              |RCC_PERIPHCLK_I2C2|RCC_PERIPHCLK_SPI3
                              |RCC_PERIPHCLK_SPI2|RCC_PERIPHCLK_SPI1
                              |RCC_PERIPHCLK_USART1|RCC_PERIPHCLK_USART10
                              |RCC_PERIPHCLK_UART9;
  PeriphClkInitStruct.PLL2.PLL2M = 24;
  PeriphClkInitStruct.PLL2.PLL2N = 168;
  PeriphClkInitStruct.PLL2.PLL2P = 1;
  PeriphClkInitStruct.PLL2.PLL2Q = 2;
  PeriphClkInitStruct.PLL2.PLL2R = 2;
  PeriphClkInitStruct.PLL2.PLL2RGE = RCC_PLL2VCIRANGE_0;
  PeriphClkInitStruct.PLL2.PLL2VCOSEL = RCC_PLL2VCOMEDIUM;
  PeriphClkInitStruct.PLL2.PLL2FRACN = 0;
  PeriphClkInitStruct.PLL3.PLL3M = 24;
  PeriphClkInitStruct.PLL3.PLL3N = 192;
  PeriphClkInitStruct.PLL3.PLL3P = 4;
  PeriphClkInitStruct.PLL3.PLL3Q = 4;
  PeriphClkInitStruct.PLL3.PLL3R = 4;
  PeriphClkInitStruct.PLL3.PLL3RGE = RCC_PLL3VCIRANGE_0;
  PeriphClkInitStruct.PLL3.PLL3VCOSEL = RCC_PLL3VCOMEDIUM;
  PeriphClkInitStruct.PLL3.PLL3FRACN = 0;
  PeriphClkInitStruct.Spi123ClockSelection = RCC_SPI123CLKSOURCE_PLL2;
  PeriphClkInitStruct.Usart16ClockSelection = RCC_USART16910CLKSOURCE_PLL2;
  PeriphClkInitStruct.I2c123ClockSelection = RCC_I2C1235CLKSOURCE_PLL3;
  PeriphClkInitStruct.UsbClockSelection = RCC_USBCLKSOURCE_PLL3;
  PeriphClkInitStruct.AdcClockSelection = RCC_ADCCLKSOURCE_PLL3;
  if (HAL_RCCEx_PeriphCLKConfig(&PeriphClkInitStruct) != HAL_OK)
  {
    Error_Handler();
  }
}

void HAL_TIM_PeriodElapsedCallback(TIM_HandleTypeDef *htim)
{
  if (htim->Instance == TIM17) {
    HAL_IncTick();
  }
}

void Error_Handler(void)
{
  __disable_irq();
  while (1)
  {
  }
}

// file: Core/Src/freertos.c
/* USER CODE BEGIN Header */
/**
  ******************************************************************************
  * File Name          : freertos.c
  * Description        : Code for freertos applications
  ******************************************************************************
  * @attention
  *
  * Copyright (c) 2024 STMicroelectronics.
  * All rights reserved.
  *
  * This software is licensed under terms that can be found in the LICENSE file
  * in the root directory of this software component.
  * If no LICENSE file comes with this software, it is provided AS-IS.
  *
  ******************************************************************************
  */
/* USER CODE END Header */

#include "FreeRTOS.h"
#include "task.h"
#include "main.h"
#include "cmsis_os.h"

/* USER CODE BEGIN Includes */
#include "spi.h"
/* USER CODE END Includes */

/* USER CODE BEGIN Variables */
RAM_D1 uint8_t ucHeap[ configTOTAL_HEAP_SIZE ];
/* USER CODE END Variables */
/* Definitions for defaultTask */
osThreadId_t defaultTaskHandle;
const osThreadAttr_t defaultTask_attributes = {
  .name = "defaultTask",
  .stack_size = 1024 * 4,
  .priority = (osPriority_t) osPriorityNormal,
};

/* USER CODE BEGIN FunctionPrototypes */
/* implement the functions below at application level */
__weak void RM_RTOS_Init(void) {}
__weak void RM_RTOS_Mutexes_Init(void) {}
__weak void RM_RTOS_Semaphores_Init(void) {}
__weak void RM_RTOS_Timers_Init(void) {}
__weak void RM_RTOS_Queues_Init(void) {}
__weak void RM_RTOS_Threads_Init(void) {}
__weak void RM_RTOS_Ready(void) {}
__weak void RM_RTOS_Default_Task(const void *argument) { UNUSED(argument); }
/* USER CODE END FunctionPrototypes */

void StartDefaultTask(void *argument);

extern void MX_USB_DEVICE_Init(void);
void MX_FREERTOS_Init(void); /* (MISRA C 2004 rule 8.1) */

/* Hook prototypes */
void configureTimerForRunTimeStats(void);
unsigned long getRunTimeCounterValue(void);
void vApplicationStackOverflowHook(xTaskHandle xTask, signed char *pcTaskName);

/* USER CODE BEGIN 1 */
/* Functions needed when configGENERATE_RUN_TIME_STATS is on */
__weak void configureTimerForRunTimeStats(void)
{

}

__weak unsigned long getRunTimeCounterValue(void)
{
return 0;
}
/* USER CODE END 1 */

/* USER CODE BEGIN 4 */
__weak void vApplicationStackOverflowHook(xTaskHandle xTask, signed char *pcTaskName)
{
  /* Run time stack overflow checking is performed if
  configCHECK_FOR_STACK_OVERFLOW is defined to 1 or 2. This hook function is
  called if a stack overflow is detected. */
  (void)xTask;
  (void)pcTaskName;
}
/* USER CODE END 4 */

void MX_FREERTOS_Init(void) {
  /* USER CODE BEGIN Init */
  RM_RTOS_Init();
  /* USER CODE END Init */

  /* USER CODE BEGIN RTOS_MUTEX */
  /* add mutexes, ... */
  RM_RTOS_Mutexes_Init();
  /* USER CODE END RTOS_MUTEX */

  /* USER CODE BEGIN RTOS_SEMAPHORES */
  /* add semaphores, ... */
  RM_RTOS_Semaphores_Init();
  /* USER CODE END RTOS_SEMAPHORES */

  /* USER CODE BEGIN RTOS_TIMERS */
  /* start timers, add new ones, ... */
  RM_RTOS_Timers_Init();
  /* USER CODE END RTOS_TIMERS */

  /* USER CODE BEGIN RTOS_QUEUES */
  /* add queues, ... */
  RM_RTOS_Queues_Init();
  /* USER CODE END RTOS_QUEUES */

  /* Create the thread(s) */
  /* creation of defaultTask */
  defaultTaskHandle = osThreadNew(StartDefaultTask, NULL, &defaultTask_attributes);

  /* USER CODE BEGIN RTOS_THREADS */
  /* add threads, ... */
  RM_RTOS_Threads_Init();
  RM_RTOS_Ready();
  /* USER CODE END RTOS_THREADS */

}

void StartDefaultTask(void *argument)
{
  /* init code for USB_DEVICE */
  MX_USB_DEVICE_Init();
  /* USER CODE BEGIN StartDefaultTask */
  RM_RTOS_Default_Task(argument);
  /* Infinite loop */
  for(;;)
  {
    osDelay(1);
  }
  /* USER CODE END StartDefaultTask */
}
